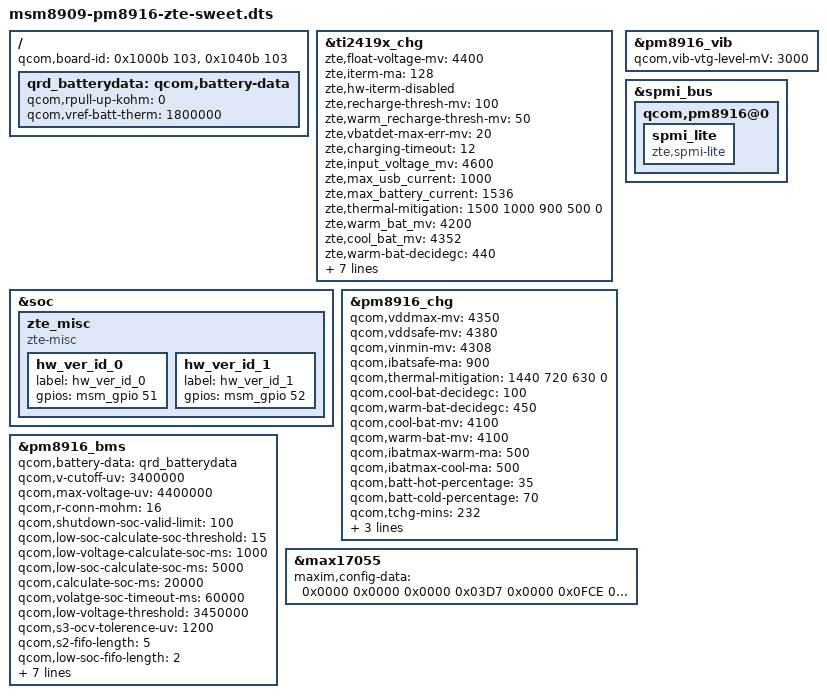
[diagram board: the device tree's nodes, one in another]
/*
 * Copyright (c) 2015, The Linux Foundation. All rights reserved.
 *
 * This program is free software; you can redistribute it and/or modify
 * it under the terms of the GNU General Public License version 2 and
 * only version 2 as published by the Free Software Foundation.
 *
 * This program is distributed in the hope that it will be useful,
 * but WITHOUT ANY WARRANTY; without even the implied warranty of
 * MERCHANTABILITY or FITNESS FOR A PARTICULAR PURPOSE.  See the
 * GNU General Public License for more details.
 */

/dts-v1/;

#include "msm8909-pm8916-qrd-skut.dtsi"
#include "msm8909-pm8916-zte-sweet.dtsi"
#include "msm8909-camera-sensor-zte-sweet.dtsi"
/ {
	qcom,board-id= <0x1000b 103>, <0x1040b 103>;
};
&ti2419x_chg {
	zte,float-voltage-mv = <4400>;
	zte,iterm-ma = <128>;
	zte,hw-iterm-disabled;
	/*zte,charging-disabled; changed by zte */
	zte,recharge-thresh-mv = <100>;
	zte,warm_recharge-thresh-mv = <50>;
	zte,vbatdet-max-err-mv = <20>;
	zte,charging-timeout = <12>;
	zte,input_voltage_mv = <4600>;
	zte,max_usb_current = <1000>;
	zte,max_battery_current = <1536>;
	zte,thermal-mitigation = <1500 1000 900 500 0>;
	zte,warm_bat_mv = <4200>;
	zte,cool_bat_mv = <4352>;
	zte,warm-bat-decidegc = <440>;
	zte,cool-bat-decidegc = <100>;
	zte,hot-bat-decidegc = <500>;
	zte,cold-bat-decidegc = <20>;
	zte,warm_bat_chg_ma = <512>;
	zte,cool_bat_chg_ma = <512>;
	zte,batt-hot-percentage = <25>; /*for battery therm correcting*/
	zte,batt-cold-percentage= <80>; /*for battery therm correcting*/
};


/ {
	qrd_batterydata: qcom,battery-data {
		qcom,rpull-up-kohm = <0>;
		qcom,vref-batt-therm = <1800000>;

		#include "batterydata-qrd-4v35-2520mah.dtsi"
	};
};

&soc {
		zte_misc {
			compatible = "zte-misc";
			/*zte,use-ti-charger-internal-battery-switch;*/
			hw_ver_id_0 {
				label = "hw_ver_id_0";
				gpios = <&msm_gpio 51 0>;
			};
			hw_ver_id_1 {
				label = "hw_ver_id_1";
				gpios = <&msm_gpio 52 0>;
			};
		};
};
&pm8916_chg {
		status = "ok";

		qcom,vddmax-mv = <4350>;
		qcom,vddsafe-mv = <4380>;
		qcom,vinmin-mv = <4308>;
		qcom,ibatsafe-ma = <900>;/*for p890a12/13 as ibat_max*/
		qcom,thermal-mitigation = <1440 720 630 0>;
		qcom,cool-bat-decidegc = <100>;
		qcom,warm-bat-decidegc = <450>;
		qcom,cool-bat-mv = <4100>;
		qcom,warm-bat-mv = <4100>;
		qcom,ibatmax-warm-ma = <500>;
		qcom,ibatmax-cool-ma = <500>;
		qcom,batt-hot-percentage = <35>;  /*0-45 DegC for for p890a12/13*/
		qcom,batt-cold-percentage = <70>; /*0-45 DegC for for p890a12/13*/
		qcom,tchg-mins = <232>;
		qcom,chg-vadc = <&pm8916_vadc>;
		qcom,chg-adc_tm = <&pm8916_adc_tm>;
		qcom,bpd-detection = "bpd_thm";
	};

&pm8916_bms {
		status = "ok";
		qcom,battery-data = <&qrd_batterydata>;

		qcom,v-cutoff-uv = <3400000>;
		qcom,max-voltage-uv = <4400000>;
		qcom,r-conn-mohm = <16>;
		qcom,shutdown-soc-valid-limit = <100>;
		qcom,low-soc-calculate-soc-threshold = <15>;
		qcom,low-voltage-calculate-soc-ms = <1000>;
		qcom,low-soc-calculate-soc-ms = <5000>;
		qcom,calculate-soc-ms = <20000>;
		qcom,volatge-soc-timeout-ms = <60000>;
		qcom,low-voltage-threshold = <3450000>;
		qcom,s3-ocv-tolerence-uv = <1200>;
		qcom,s2-fifo-length = <5>;
		qcom,low-soc-fifo-length = <2>;
		qcom,bms-vadc = <&pm8916_vadc>;
		qcom,bms-adc_tm = <&pm8916_adc_tm>;
		qcom,pmic-revid = <&pm8916_revid>;

		qcom,force-s3-on-suspend;
		qcom,force-s2-in-charging;
		qcom,report-charger-eoc;
		qcom,resume-soc = <99>;
	};

&pm8916_vib {
		qcom,vib-vtg-level-mV = <3000>;
};
&spmi_bus {

	qcom,pm8916@0 {
		/*spmi_lite is for batt present detect*/
		spmi_lite {
			compatible = "zte,spmi-lite";
		};
	};
};
&max17055 {
	maxim,config-data = /bits/ 16 <
		0x0000 0x0000 0x0000 0x03D7 0x0000		/* A/D measurement */
		0x0FCE 0xE196 0x0000 0x0000 0x2214 0x00d8 0xe000	/* Alert / Status */
		0x0000 0x0000 0x040c 0x00c0 0x0000 0xaa64 0x8400	/* App data */
		0x0000 0x4412 0x0000 0x0000 0x0000 0x860b		/* Configs */
		0x0049 0x343f 0x5400 0x2483 0x0c86 0x0a07		/* Cell Data */
		0x7d00 0xaad0 0xb7b0 0xb9a0 0xbc50 0xbda0 0xbe80 0xbfb0		/* Model Data Begin*/
		0xc210 0xc360 0xc690 0xc9b0 0xcc50 0xceb0 0xd530 0xdb40
		0x0020 0x0180 0x1730 0x0d00 0x19e0 0x13c0 0x12f0 0x0f80
		0x0a50 0x08f0 0x06f0 0x07f0 0x0890 0x06e0 0x05f0 0x05f0
		0x0100 0x0100 0x0100 0x0100 0x0100 0x0100 0x0100 0x0100
		0x0100 0x0100 0x0100 0x0100 0x0100 0x0100 0x0100 0x0100		/* Model Data End*/
	>;
};

